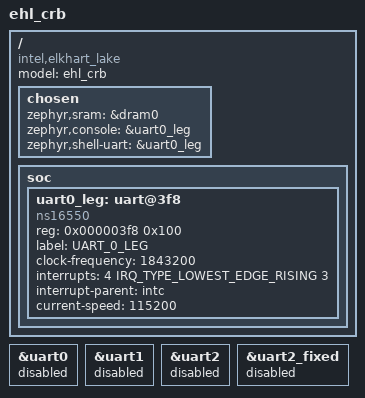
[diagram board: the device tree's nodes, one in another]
/*
 * Copyright (c) 2020 Intel Corporation
 *
 * SPDX-License-Identifier: Apache-2.0
 */

/dts-v1/;

#include <mem.h>

#define DT_DRAM_SIZE		DT_SIZE_M(2048)

#include <elkhart_lake.dtsi>

&uart0 {
	status = "disabled";
};
&uart1 {
	status = "disabled";
};
&uart2 {
	status = "disabled";
};

&uart2_fixed {
	status = "disabled";
};

/ {
	model = "ehl_crb";
	compatible = "intel,elkhart_lake";

	chosen {
		zephyr,sram = &dram0;
		zephyr,console = &uart0_leg;
		zephyr,shell-uart = &uart0_leg;
	};
    
    soc {
        uart0_leg: uart@3f8{
            compatible = "ns16550";
            reg = <0x000003f8 0x100>;

            label = "UART_0_LEG";
            clock-frequency = <1843200>;
            interrupts = <4 IRQ_TYPE_LOWEST_EDGE_RISING 3>;
            interrupt-parent = <&intc>;
            
            status = "disabled";
        };
    };
};

// enabled and modified devices
&uart0_leg {
    status = "okay";
    current-speed = <115200>;
};
